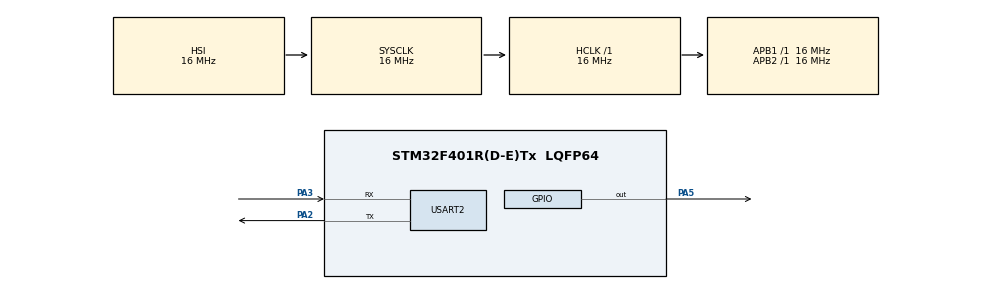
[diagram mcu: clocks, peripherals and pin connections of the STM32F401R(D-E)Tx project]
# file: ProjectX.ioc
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Mcu.Family=STM32F4
Mcu.Name=STM32F401R(D-E)Tx
Mcu.Package=LQFP64
NVIC.PriorityGroup=NVIC_PRIORITYGROUP_4
NVIC.TIM5_IRQn=true\:15\:0\:false\:false\:true\:false\:true\:true
NVIC.TimeBase=TIM5_IRQn
NVIC.TimeBaseIP=TIM5
NVIC.USART2_IRQn=true\:0\:0\:false\:false\:true\:true\:true\:true
PA13.Mode=Serial_Wire
PA13.Signal=SYS_JTMS-SWDIO
PA14.Mode=Serial_Wire
PA14.Signal=SYS_JTCK-SWCLK
PA2.Mode=Asynchronous
PA2.Signal=USART2_TX
PA3.Mode=Asynchronous
PA3.Signal=USART2_RX
PA5.Signal=GPIO_Output
PH0\ -\ OSC_IN.Mode=HSE-External-Oscillator
PH0\ -\ OSC_IN.Signal=RCC_OSC_IN
PH1\ -\ OSC_OUT.Mode=HSE-External-Oscillator
PH1\ -\ OSC_OUT.Signal=RCC_OSC_OUT
ProjectManager.HeapSize=0x200
ProjectManager.StackSize=0x400
ProjectManager.TargetToolchain=Makefile
RCC.AHBFreq_Value=16000000
RCC.APB1Freq_Value=16000000
RCC.APB2Freq_Value=16000000
RCC.CortexFreq_Value=16000000
RCC.HSE_VALUE=25000000
RCC.HSI_VALUE=16000000
RCC.LSE_VALUE=32768
RCC.SYSCLKFreq_VALUE=16000000
RCC.VCOOutputFreq_Value=192000000
USART2.VirtualMode=VM_ASYNC
VP_RTC_VS_RTC_Activate.Mode=RTC_Enabled
VP_SYS_VS_tim5.Mode=TIM5
board=custom

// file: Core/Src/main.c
/* USER CODE BEGIN Header */
/**
 ******************************************************************************
 * @file           : main.c
 * @brief          : Main program body
 ******************************************************************************
 * @attention
 *
 * Copyright (c) 2024 STMicroelectronics.
 * All rights reserved.
 *
 * This software is licensed under terms that can be found in the LICENSE file
 * in the root directory of this software component.
 * If no LICENSE file comes with this software, it is provided AS-IS.
 *
 ******************************************************************************
 */
/* USER CODE END Header */
#include "main.h"
#include "rtc.h"
#include "usart.h"
#include "gpio.h"

void SystemClock_Config(void);

/* USER CODE BEGIN 0 */
uint8_t msg[] = "Hello, UART Interrupt Mode!\r\n";

/* USER CODE END 0 */

int main(void)
{

  /* MCU Configuration--------------------------------------------------------*/

  /* Reset of all peripherals, Initializes the Flash interface and the Systick. */
  HAL_Init();

  /* Configure the system clock */
  SystemClock_Config();

  /* Initialize all configured peripherals */
  MX_GPIO_Init();
  MX_RTC_Init();
  MX_USART2_UART_Init();
  /* USER CODE BEGIN 2 */

  HAL_UART_Transmit_IT(&huart2, '0', 1);

  /* USER CODE END 2 */

  /* Infinite loop */
  /* USER CODE BEGIN WHILE */
  while (1)
  {
    HAL_GPIO_TogglePin(GPIOA, GPIO_PIN_5);
    HAL_Delay(500);
    /* USER CODE END WHILE */

  }
}

void HAL_UART_TxCpltCallback(UART_HandleTypeDef *huart)
{
  // Transmission complete callback
  if (huart->Instance == USART2)
  {
    // Transmission complete
    HAL_UART_Transmit_IT(&huart2, msg, sizeof(msg) - 1);
  }
}

void SystemClock_Config(void)
{
  RCC_OscInitTypeDef RCC_OscInitStruct = {0};
  RCC_ClkInitTypeDef RCC_ClkInitStruct = {0};

  /** Configure the main internal regulator output voltage
   */
  __HAL_RCC_PWR_CLK_ENABLE();
  __HAL_PWR_VOLTAGESCALING_CONFIG(PWR_REGULATOR_VOLTAGE_SCALE2);

  /** Initializes the RCC Oscillators according to the specified parameters
   * in the RCC_OscInitTypeDef structure.
   */
  RCC_OscInitStruct.OscillatorType = RCC_OSCILLATORTYPE_HSI | RCC_OSCILLATORTYPE_LSI;
  RCC_OscInitStruct.HSIState = RCC_HSI_ON;
  RCC_OscInitStruct.HSICalibrationValue = RCC_HSICALIBRATION_DEFAULT;
  RCC_OscInitStruct.LSIState = RCC_LSI_ON;
  RCC_OscInitStruct.PLL.PLLState = RCC_PLL_NONE;
  if (HAL_RCC_OscConfig(&RCC_OscInitStruct) != HAL_OK)
  {
    Error_Handler();
  }

  /** Initializes the CPU, AHB and APB buses clocks
   */
  RCC_ClkInitStruct.ClockType = RCC_CLOCKTYPE_HCLK | RCC_CLOCKTYPE_SYSCLK | RCC_CLOCKTYPE_PCLK1 | RCC_CLOCKTYPE_PCLK2;
  RCC_ClkInitStruct.SYSCLKSource = RCC_SYSCLKSOURCE_HSI;
  RCC_ClkInitStruct.AHBCLKDivider = RCC_SYSCLK_DIV1;
  RCC_ClkInitStruct.APB1CLKDivider = RCC_HCLK_DIV1;
  RCC_ClkInitStruct.APB2CLKDivider = RCC_HCLK_DIV1;

  if (HAL_RCC_ClockConfig(&RCC_ClkInitStruct, FLASH_LATENCY_0) != HAL_OK)
  {
    Error_Handler();
  }
}

void HAL_TIM_PeriodElapsedCallback(TIM_HandleTypeDef *htim)
{
  if (htim->Instance == TIM5)
  {
    HAL_IncTick();
  }
}

void Error_Handler(void)
{
  __disable_irq();
  while (1)
  {
  }
}
